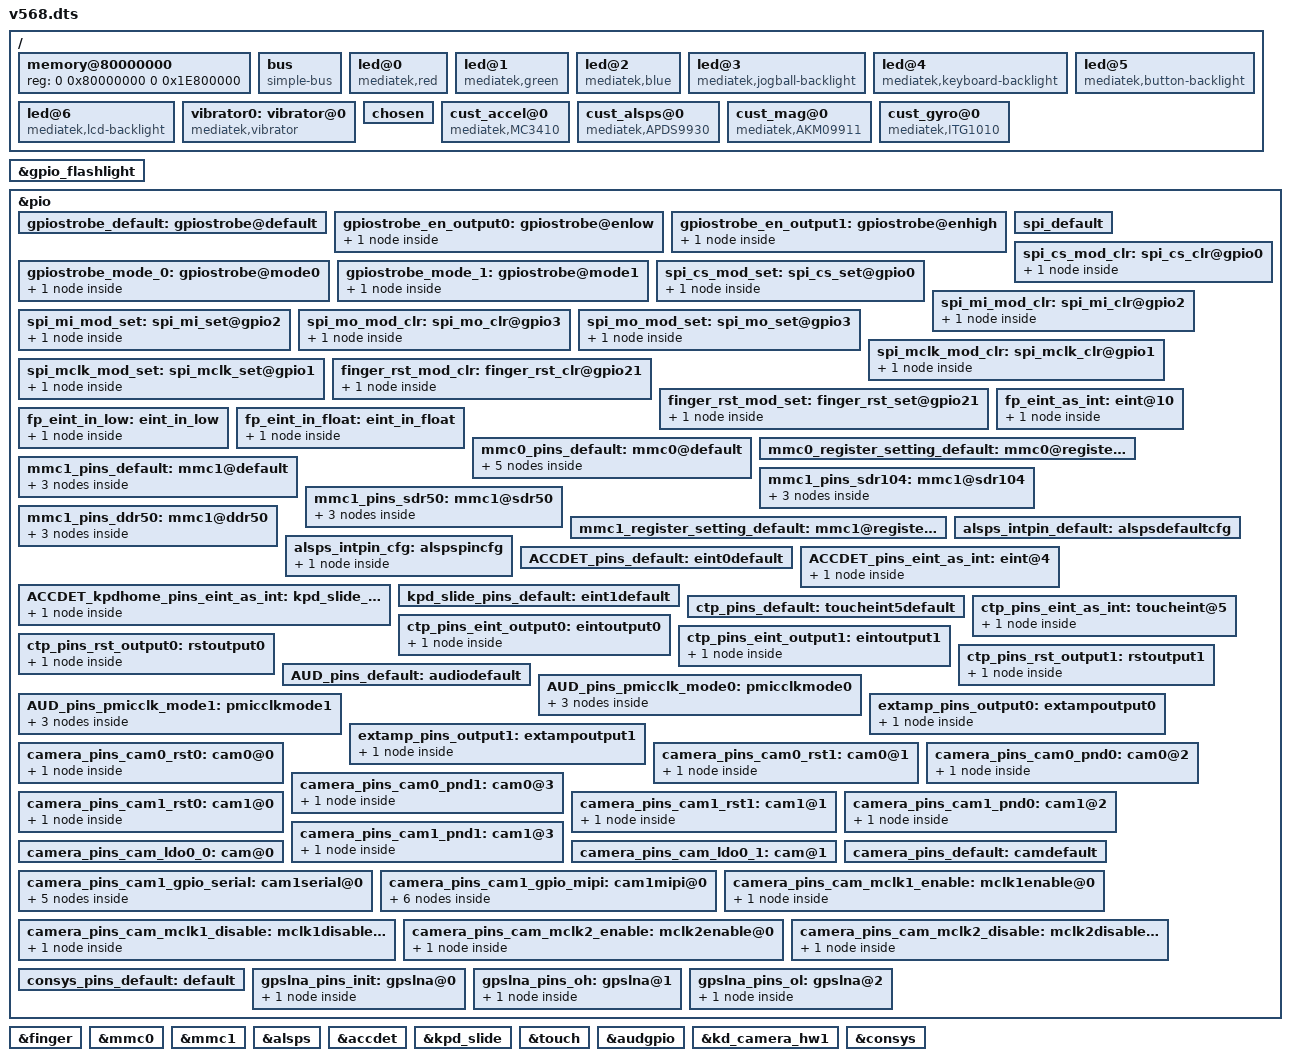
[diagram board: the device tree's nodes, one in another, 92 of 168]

/dts-v1/;

#include "mt6580.dtsi"

/ {
	memory@80000000 {
		device_type = "memory";
		reg = <0 0x80000000 0 0x1E800000>;
	};

	bus {
		compatible = "simple-bus";
		#address-cells = <1>;
		#size-cells = <1>;
		ranges = <0 0 0 0xffffffff>;
	};

	led@0 {
		compatible = "mediatek,red";
		led_mode = <0>;
		data = <1>;
		pwm_config = <0 0 0 0 0>;
	};
	led@1 {
		compatible = "mediatek,green";
		led_mode = <0>;
		data = <1>;
		pwm_config = <0 0 0 0 0>;
	};
	led@2 {
		compatible = "mediatek,blue";
		led_mode = <0>;
		data = <1>;
		pwm_config = <0 0 0 0 0>;
	};
	led@3 {
		compatible = "mediatek,jogball-backlight";
		led_mode = <0>;
		data = <1>;
		pwm_config = <0 0 0 0 0>;
	};
	led@4 {
		compatible = "mediatek,keyboard-backlight";
		led_mode = <0>;
		data = <1>;
		pwm_config = <0 0 0 0 0>;
	};
	led@5 {
		compatible = "mediatek,button-backlight";
		led_mode = <3>;
		data = <4>;
		pwm_config = <0 0 0 0 0>;
	};
	led@6 {
		compatible = "mediatek,lcd-backlight";
		led_mode = <5>;
		data = <1>;
		pwm_config = <0 0 0 0 0>;
	};
	vibrator0:vibrator@0 {
		compatible = "mediatek,vibrator";
		vib_timer = <25>;
		vib_limit = <9>;
		vib_vol= <6>;
	};

	/* chosen */
chosen {
	bootargs = "console=tty0 console=ttyMT0,921600n1 root=/dev/ram initrd=0x84000000,0x400000 loglevel=8";
	/* fpga may has no lk, we need to specify display info here */
	/* fb buffer is reserved using this dts by memory node above */
	atag,videolfb-fb_base = <0x9E800000>;
	atag,videolfb-islcmfound = <1>;
	atag,videolfb-fps= <6000>;
	atag,videolfb-vramSize= <0x01800000>;
	atag,videolfb-lcmname= "nt35590_AUO";
};
	/*  start sensor */
		cust_accel@0 {
		compatible				= "mediatek,MC3410";
		i2c_num					= <2>;
		i2c_addr				= <0x4c 0 0 0>;
		direction				= <4>;
		power_id				= <0xffff>;
		power_vol				= <0>;
		firlen					= <0>;
		is_batch_supported			= <0>;
		};
		cust_alsps@0 {
		compatible				= "mediatek,APDS9930";
		i2c_num					= <2>;
		i2c_addr				= <0x72 0 0 0>;
		polling_mode_ps			= <1>;
		polling_mode_als		= <1>;
		power_id				= <0xffff>;
		power_vol				= <0>;
/* Total has 15 level*/
		als_level	= <0 125 319 525 1091 2480 3058 5115 8589 10769 12857 17807 22091 65535 65535>;
/*  Total has 16 range*/
		als_value	= <0 133 303 504 1002 2003 3006 5003 8002 10000 12000 16000 20000 20000 20000 20000>;
		ps_threshold_high		=  <180>;
		ps_threshold_low		=  <120>;
		is_batch_supported_ps	= <0>;
		is_batch_supported_als	= <0>;
		};
		cust_mag@0 {
		compatible				= "mediatek,AKM09911";
		i2c_num					= <2>;
		i2c_addr				= <0x0D 0 0 0>;
		direction				= <4>;
		power_id				= <0xffff>;
		power_vol				= <0>;
		is_batch_supported			= <0>;
		};
		cust_gyro@0 {
		compatible				= "mediatek,ITG1010";
		i2c_num					= <2>;
		i2c_addr				= <0x68 0 0 0>;
		direction				= <1>;
		power_id				= <0xffff>;
		power_vol				= <0>;
		firlen					= <0>;
		is_batch_supported			= <0>;
		};


  /* end sensor */
};

/* yan add for flashlight with gpio mode */
&gpio_flashlight {
	pinctrl-names = "default", "flash_en_low", "flash_en_high", "flash_mode_0", "flash_mode_1";
	pinctrl-0 = <&gpiostrobe_default>;
	pinctrl-1 = <&gpiostrobe_en_output0>;
	pinctrl-2 = <&gpiostrobe_en_output1>;
	pinctrl-3 = <&gpiostrobe_mode_0>;
	pinctrl-4 = <&gpiostrobe_mode_1>;
	status = "okay";
};
&pio {
	gpiostrobe_default: gpiostrobe@default {
	};
	gpiostrobe_en_output0: gpiostrobe@enlow {
		pins_cmd_dat {
			pins = <PINMUX_GPIO12__FUNC_GPIO12>;
			slew-rate = <1>;
			output-low;
		};
	};
	gpiostrobe_en_output1: gpiostrobe@enhigh {
		pins_cmd_dat {
			pins = <PINMUX_GPIO12__FUNC_GPIO12>;
			slew-rate = <1>;
			output-high;
		};
	};
	gpiostrobe_mode_0: gpiostrobe@mode0 {
		pins_cmd_dat {
			pins = <PINMUX_GPIO15__FUNC_GPIO15>;
		};
	};
	gpiostrobe_mode_1: gpiostrobe@mode1 {
		pins_cmd_dat {
			pins = <PINMUX_GPIO15__FUNC_UCTS1>;
		};
	};
};
/* yan end */

/* add for fingerprint */
&pio {
	spi_default: spi_default {
	};

	spi_cs_mod_clr: spi_cs_clr@gpio0 {
		pins_cmd_dat {
			pins = <PINMUX_GPIO0__FUNC_GPIO0>;
			slew-rate = <1>;
			output-high;
		};
	};
	spi_cs_mod_set: spi_cs_set@gpio0 {
		pins_cmd_dat {
			pins = <PINMUX_GPIO0__FUNC_SPI1_CS>;
			input-enable;
		};
	};	
	spi_mi_mod_clr: spi_mi_clr@gpio2 {
		pins_cmd_dat {
			pins = <PINMUX_GPIO2__FUNC_GPIO2>;
			slew-rate = <1>;
			output-high;
		};
	};
	spi_mi_mod_set: spi_mi_set@gpio2 {
		pins_cmd_dat {
			pins = <PINMUX_GPIO2__FUNC_SPI1_MISO>;
			input-enable;
		};
	};	
	spi_mo_mod_clr: spi_mo_clr@gpio3 {
		pins_cmd_dat {
			pins = <PINMUX_GPIO3__FUNC_GPIO3>;
			slew-rate = <1>;
			output-low;
		};
	};
	spi_mo_mod_set: spi_mo_set@gpio3 {
		pins_cmd_dat {
			pins = <PINMUX_GPIO3__FUNC_SPI1_MOSI>;
			input-enable;
		};
	};	
	spi_mclk_mod_clr: spi_mclk_clr@gpio1 {
		pins_cmd_dat {
			pins = <PINMUX_GPIO1__FUNC_GPIO1>;
			slew-rate = <1>;
			output-low;
		};
	};
	spi_mclk_mod_set: spi_mclk_set@gpio1{
		pins_cmd_dat {
			pins = <PINMUX_GPIO1__FUNC_SPI1_SCK>;
			input-enable;
		};
	};	
	finger_rst_mod_clr: finger_rst_clr@gpio21 {
		pins_cmd_dat {
			pins = <PINMUX_GPIO21__FUNC_GPIO21>;
			slew-rate = <1>;
			output-low;
		};
	};
	finger_rst_mod_set: finger_rst_set@gpio21 {
		pins_cmd_dat {
			pins = <PINMUX_GPIO21__FUNC_GPIO21>;
			slew-rate = <1>;
			output-high;
		};
	};
	fp_eint_as_int: eint@10 {
		pins_cmd_dat {
			pins = <PINMUX_GPIO10__FUNC_EINT10>;
			slew-rate = <0>;
			bias-disable;
		};
	};
	fp_eint_in_low: eint_in_low {
		pins_cmd_dat {
			pins = <PINMUX_GPIO10__FUNC_GPIO10>;
			slew-rate = <1>;
			output-low;
			bias-pull-down = <00>;
		};
	};
	fp_eint_in_float: eint_in_float {
		pins_cmd_dat {
			pins = <PINMUX_GPIO10__FUNC_GPIO10>;
			slew-rate = <1>;
			output-high;
			bias-pull-down = <00>;
		};
	};	
/*fp_pow_mod_clr: finger_pow_clr@gpio15 {
		pins_cmd_dat {
			pins = <PINMUX_GPIO15__FUNC_GPIO15>;
			slew-rate = <1>;
			output-low;
		};
	};
	fp_pow_mod_set: finger_pow_set@gpio15 {
		pins_cmd_dat {
			pins = <PINMUX_GPIO15__FUNC_GPIO15>;
			slew-rate = <1>;
			output-high;
		};
	};	*/
};

&finger {
	pinctrl-names = "spi_default", "spi_cs_clr","spi_cs_set","spi_mi_clr","spi_mi_set",
					"spi_mo_clr","spi_mo_set","spi_mclk_clr","spi_mclk_set",
					"finger_rst_clr","finger_rst_set","eint","eint_clr","eint_set","finger_pow_clr","finger_pow_set";
	pinctrl-0 = <&spi_default>;
	pinctrl-1 = <&spi_cs_mod_clr>;
	pinctrl-2 = <&spi_cs_mod_set>;
	pinctrl-3 = <&spi_mi_mod_clr>;
	pinctrl-4 = <&spi_mi_mod_set>;
	pinctrl-5 = <&spi_mo_mod_clr>;
	pinctrl-6 = <&spi_mo_mod_set>;
	pinctrl-7 = <&spi_mclk_mod_clr>;
	pinctrl-8 = <&spi_mclk_mod_set>;	
	pinctrl-9 = <&finger_rst_mod_clr>;
	pinctrl-10 = <&finger_rst_mod_set>;
	pinctrl-11 = <&fp_eint_as_int>;
	pinctrl-12 = <&fp_eint_in_low>;
	pinctrl-13 = <&fp_eint_in_float>;
/*	pinctrl-14 = <&fp_pow_mod_clr>;
	pinctrl-15 = <&fp_pow_mod_set>;	*/
	status = "okay";
};
/* add end*/

/* mmc start */
&mmc0 {
	clk_src = /bits/ 8 <MSDC0_CLKSRC_208MHZ>;
	bus-width = <8>;
	max-frequency = <208000000>;
	cap-mmc-highspeed;
	msdc-sys-suspend;
	mmc-hs200-1_8v;
	non-removable;
	pinctl = <&mmc0_pins_default>;
	register_setting = <&mmc0_register_setting_default>;
	host_function = /bits/ 8 <MSDC_EMMC>;
	bootable;
	status = "okay";
};

&mmc1 {
	clk_src = /bits/ 8 <MSDC1_CLKSRC_187MHZ>;
	bus-width = <4>;
	max-frequency = <208000000>;
	msdc-sys-suspend;
	cap-sd-highspeed;
	sd-uhs-sdr12;
	sd-uhs-sdr25;
	sd-uhs-sdr50;
	sd-uhs-sdr104;
	pinctl = <&mmc1_pins_default>;
	pinctl_sdr104 = <&mmc1_pins_sdr104>;
	pinctl_sdr50 = <&mmc1_pins_sdr50>;
	pinctl_ddr50 = <&mmc1_pins_ddr50>;
	register_setting = <&mmc1_register_setting_default>;
	host_function = /bits/ 8 <MSDC_SD>;
	cd_level = /bits/ 8 <MSDC_CD_LOW>;
	cd-gpios = <&pio 16 0>;
	status = "okay";
};

&pio {
	mmc0_pins_default: mmc0@default {
		pins_cmd {
			drive-strength = /bits/ 8 <2>;
		};
		pins_dat {
			drive-strength = /bits/ 8 <2>;
		};
		pins_clk {
			drive-strength = /bits/ 8 <2>;
		};
		pins_rst {
			drive-strength = /bits/ 8 <2>;
		};
		pins_ds {
			drive-strength = /bits/ 8 <2>;
		};
	};

	mmc0_register_setting_default: mmc0@register_default {
		dat0rddly      = /bits/ 8 <0>;
		dat1rddly      = /bits/ 8 <0>;
		dat2rddly      = /bits/ 8 <0>;
		dat3rddly      = /bits/ 8 <0>;
		dat4rddly      = /bits/ 8 <0>;
		dat5rddly      = /bits/ 8 <0>;
		dat6rddly      = /bits/ 8 <0>;
		dat7rddly      = /bits/ 8 <0>;
		datwrddly      = /bits/ 8 <0>;
		cmdrrddly      = /bits/ 8 <0>;
		cmdrddly       = /bits/ 8 <0>;
		cmd_edge = /bits/ 8 <MSDC_SMPL_FALLING>;
		rdata_edge = /bits/ 8 <MSDC_SMPL_FALLING>;
		wdata_edge = /bits/ 8 <MSDC_SMPL_FALLING>;

		ett-hs200-cells = <12>;
		ett-hs200-default = <OFFSET_MSDC_PATCH_BIT0	MSDC_PB0_INT_DAT_LATCH_CK_SEL 0x0
			OFFSET_MSDC_PATCH_BIT0  MSDC_PB0_CKGEN_MSDC_DLY_SEL   0x0
			OFFSET_MSDC_PATCH_BIT1  MSDC_PB1_CMD_RSP_TA_CNTR      0x1
			OFFSET_MSDC_IOCON       MSDC_IOCON_RSPL               0x1
			OFFSET_MSDC_PAD_TUNE0   MSDC_PAD_TUNE0_CMDRDLY        0x0
			OFFSET_MSDC_PAD_TUNE0   MSDC_PAD_TUNE0_CMDRRDLY       0x0
			OFFSET_MSDC_PATCH_BIT1  MSDC_PB1_WRDAT_CRCS_TA_CNTR   0x1
			OFFSET_MSDC_PAD_TUNE0   MSDC_PAD_TUNE0_DATWRDLY       0x0
			OFFSET_MSDC_IOCON       MSDC_IOCON_W_D_SMPL           0x1
			OFFSET_MSDC_DAT_RDDLY0  MSDC_DAT_RDDLY0_D0            0x0
			OFFSET_MSDC_PAD_TUNE0   MSDC_PAD_TUNE0_DATRRDLY       0x0
			OFFSET_MSDC_PATCH_BIT0  MSDC_PB0_RD_DAT_SEL           0x1>;
	};

	mmc1_pins_default: mmc1@default {
		pins_cmd {
			drive-strength = /bits/ 8 <3>;
		};
		pins_dat {
			drive-strength = /bits/ 8 <3>;
		};
		pins_clk {
			drive-strength = /bits/ 8 <3>;
		};
	};

	mmc1_pins_sdr104: mmc1@sdr104 {
		pins_cmd {
			drive-strength = /bits/ 8 <2>;
		};
		pins_dat {
			drive-strength = /bits/ 8 <2>;
		};
		pins_clk {
			drive-strength = /bits/ 8 <3>;
		};
	};

	mmc1_pins_sdr50: mmc1@sdr50 {
		pins_cmd {
			drive-strength = /bits/ 8 <2>;
		};
		pins_dat {
			drive-strength = /bits/ 8 <2>;
		};
		pins_clk {
			drive-strength = /bits/ 8 <3>;
		};
	};

	mmc1_pins_ddr50: mmc1@ddr50 {
		pins_cmd {
			drive-strength = /bits/ 8 <2>;
		};
		pins_dat {
			drive-strength = /bits/ 8 <2>;
		};
		pins_clk {
			drive-strength = /bits/ 8 <3>;
		};
	};

	mmc1_register_setting_default: mmc1@register_default {
		dat0rddly      = /bits/ 8 <0>;
		dat1rddly      = /bits/ 8 <0>;
		dat2rddly      = /bits/ 8 <0>;
		dat3rddly      = /bits/ 8 <0>;
		datwrddly      = /bits/ 8 <0>;
		cmdrrddly      = /bits/ 8 <0>;
		cmdrddly       = /bits/ 8 <0>;
		cmd_edge = /bits/ 8 <MSDC_SMPL_FALLING>;
		rdata_edge = /bits/ 8 <MSDC_SMPL_FALLING>;
		wdata_edge = /bits/ 8 <MSDC_SMPL_FALLING>;
	};
};
/* mmc end */


&alsps {
	pinctrl-names = "pin_default", "pin_cfg";
	pinctrl-0 = <&alsps_intpin_default>;
	pinctrl-1 = <&alsps_intpin_cfg>;
	status = "okay";
};

/*
&gyro {
	pinctrl-names = "pin_default", "pin_cfg";
	pinctrl-0 = <&gyro_intpin_default>;
	pinctrl-1 = <&gyro_intpin_cfg>;
	status = "okay";
};
*/
&pio {

	alsps_intpin_default: alspsdefaultcfg {
	};
	alsps_intpin_cfg: alspspincfg {
	    pins_cmd_dat {
			pins = <PINMUX_GPIO6__FUNC_EINT6>;
		};
	};	
/*	
	gyro_intpin_cfg: gyropincfg {
	    pins_cmd_dat {
			pins = <PINMUX_GPIO16__FUNC_GPIO16>;
			slew-rate = <0>;
			bias-pull-down = <00>;
		};
	};
	gyro_intpin_default: gyrodefaultcfg {
	};
	*/
};

&accdet {
	accdet-mic-vol = <7>;
	headset-mode-setting = <0x500 0x200 1 0x1F0 0x800 0x800 0x20>;
	accdet-plugout-debounce = <20>;
	/*1:ACC mode, 2:low cost without in bias, 6:low cost with in bias*/
	accdet-mic-mode = <1>;
	/*0--MD_MAX--UP_MAX--DW_MAX*/
	headset-three-key-threshold = <0 90 240 500>;
	/*0--MD_MAX--VOICE_MAX--UP_MAX--DW_MAX*/
	headset-four-key-threshold = <0 59 123 195 450>;
	/* ACCDET GPIO standardization ACC mode use */
	pinctrl-names = "default", "state_eint_as_int", "kpdhome_state_eint_as_int"/*, "sd_msdc_eint_as_int", "sim_hot_plug_1", "sim_hot_plug_2"*/;
	pinctrl-0 = <&ACCDET_pins_default>;
	pinctrl-1 = <&ACCDET_pins_eint_as_int>;
	pinctrl-2 = <&ACCDET_kpdhome_pins_eint_as_int>;
/*		pinctrl-3 = <&msdc_eint_as_int>;
    pinctrl-4 = <&ACCDET_sim_hot_plug_1>;
	pinctrl-5 = <&ACCDET_sim_hot_plug_2>; */
	status = "okay";
};
&pio {
	ACCDET_pins_default: eint0default {
	};
	ACCDET_pins_eint_as_int: eint@4 {
		pins_cmd_dat {
			pins = <PINMUX_GPIO4__FUNC_EINT4>;
			slew-rate = <0>;
			bias-disable;
		};
	};
	ACCDET_kpdhome_pins_eint_as_int: eint@1 {
		pins_cmd_dat {
			pins = <PINMUX_GPIO65__FUNC_EINT1>;
			slew-rate = <0>;
			bias-disable;
		};
	};	
/*	msdc_eint_as_int: eint@0 {
		pins_cmd_dat {
			pins = <PINMUX_GPIO16__FUNC_EINT0>;
			slew-rate = <0>;
			bias-disable;
		};
	};
	ACCDET_sim_hot_plug_1: mt_enit@1 {
		pins_cmd_dat {
			pins = <PINMUX_GPIO77__FUNC_MD_EINT1>;
		};
	};		
	ACCDET_sim_hot_plug_2: mt_enit@2 {
		pins_cmd_dat {
			pins = <PINMUX_GPIO78__FUNC_MD_EINT2>;
		};
	}; */
};
/*ACCDET END*/


/*kpdslide begin*/
&kpd_slide{
	pinctrl-0 = <&kpd_slide_pins_default>;
	pinctrl-1 = <&kpd_slide_pins_eint_as_int>;
	status = "okay";
};
&pio {
	kpd_slide_pins_default: eint1default {
	};
	kpd_slide_pins_eint_as_int: eint@1 {
		pins_cmd_dat {
			pins = <PINMUX_GPIO65__FUNC_EINT1>;
			slew-rate = <0>;
			bias-disable;
		};
	};
};
/*kpdslide END*/

/* TOUCH GPIO standardization */
&touch {
	tpd-resolution = <720 1280>;
	use-tpd-button = <0>;
	tpd-key-num = <3>;
	tpd-key-local= <139 172 158 0>;
	tpd-key-dim-local = <90 883 100 40 230 883 100 40 370 883 100 40 0 0 0 0>;
	tpd-max-touch-num = <5>;
	tpd-filter-enable = <1>;
	tpd-filter-pixel-density = <124>;
	tpd-filter-custom-prameters = <0 0 0 0 0 0 0 0 0 0 0 0>;
	tpd-filter-custom-speed = <0 0 0>;
	pinctrl-names = "default", "state_eint_as_int", "state_eint_output0", "state_eint_output1",
		"state_rst_output0", "state_rst_output1";
	pinctrl-0 = <&ctp_pins_default>;
	pinctrl-1 = <&ctp_pins_eint_as_int>;
	pinctrl-2 = <&ctp_pins_eint_output0>;
	pinctrl-3 = <&ctp_pins_eint_output1>;
	pinctrl-4 = <&ctp_pins_rst_output0>;
	pinctrl-5 = <&ctp_pins_rst_output1>;
	status = "okay";
};
&pio {
	ctp_pins_default: toucheint5default {
	};
	ctp_pins_eint_as_int: toucheint@5 {
		pins_cmd_dat {
			pins = <PINMUX_GPIO5__FUNC_EINT5>;
			slew-rate = <0>;
			bias-disable;
		};
	};
	ctp_pins_eint_output0: eintoutput0 {
		pins_cmd_dat {
			pins = <PINMUX_GPIO5__FUNC_GPIO5>;
			slew-rate = <1>;
			output-low;
		};
	};
	ctp_pins_eint_output1: eintoutput1 {
		pins_cmd_dat {
			pins = <PINMUX_GPIO5__FUNC_GPIO5>;
			slew-rate = <1>;
			output-high;
		};
	};
	ctp_pins_rst_output0: rstoutput0 {
		pins_cmd_dat {
			pins = <PINMUX_GPIO11__FUNC_GPIO11>;
			slew-rate = <1>;
			output-low;
		};
	};
	ctp_pins_rst_output1: rstoutput1 {
		pins_cmd_dat {
			pins = <PINMUX_GPIO11__FUNC_GPIO11>;
			slew-rate = <1>;
			output-high;
		};
	};
};
/* TOUCH end */

/* AUDIO GPIO standardization */
&audgpio {
	pinctrl-names = "default", "audpmicclk-mode0", "audpmicclk-mode1", "extamp-pulllow", "extamp-pullhigh";
	pinctrl-0 = <&AUD_pins_default>;
	pinctrl-1 = <&AUD_pins_pmicclk_mode0>;
	pinctrl-2 = <&AUD_pins_pmicclk_mode1>;
	pinctrl-3 = <&extamp_pins_output0>;
	pinctrl-4 = <&extamp_pins_output1>;
	status = "okay";
};
&pio {
	AUD_pins_default: audiodefault {
	};
	AUD_pins_pmicclk_mode0: pmicclkmode0 {
		pins_cmd0_dat {
			pins = <PINMUX_GPIO26__FUNC_GPIO26>;
		};
		pins_cmd1_dat {
			pins = <PINMUX_GPIO28__FUNC_GPIO28>;
		};
		pins_cmd2_dat {
			pins = <PINMUX_GPIO27__FUNC_GPIO27>;
		};
	};
	AUD_pins_pmicclk_mode1: pmicclkmode1 {
		pins_cmd0_dat {
			pins = <PINMUX_GPIO26__FUNC_AUD_CLK_MOSI>;
		};
		pins_cmd1_dat {
			pins = <PINMUX_GPIO28__FUNC_AUD_DAT_MISO>;
		};
		pins_cmd2_dat {
			pins = <PINMUX_GPIO27__FUNC_AUD_DAT_MOSI>;
		};
	};
	extamp_pins_output0: extampoutput0 {
		pins_cmd_dat {
			pins = <PINMUX_GPIO9__FUNC_GPIO9>;
			slew-rate = <1>;
			output-low;
		};
	};
	extamp_pins_output1: extampoutput1 {
		pins_cmd_dat {
			pins = <PINMUX_GPIO9__FUNC_GPIO9>;
			slew-rate = <1>;
			output-high;
		};
	};
};
/* AUDIO end */
/* CAMERA GPIO standardization */
&pio {
	camera_pins_cam0_rst0: cam0@0 {
	    pins_cmd_dat {
			pins = <PINMUX_GPIO73__FUNC_GPIO73>;/*GPIO_CAMERA_CMRST_PIN*/
			slew-rate = <1>; /*direction 0:in, 1:out*/
			output-low;/*direction out used only. output_low or high*/
		};
	};
	camera_pins_cam0_rst1: cam0@1 {
	    pins_cmd_dat {
			pins = <PINMUX_GPIO73__FUNC_GPIO73>;/*GPIO_CAMERA_CMRST_PIN*/
			slew-rate = <1>;
			output-high;
		};
	};
	camera_pins_cam0_pnd0: cam0@2 {
	    pins_cmd_dat {
			pins = <PINMUX_GPIO71__FUNC_GPIO71>;/*GPIO_CAMERA_CMPDN_PIN*/
			slew-rate = <1>;
			output-low;
		};
	};
	camera_pins_cam0_pnd1: cam0@3 {
	    pins_cmd_dat {
			pins = <PINMUX_GPIO71__FUNC_GPIO71>;/*GPIO_CAMERA_CMPDN_PIN*/
			slew-rate = <1>;
			output-high;
		};
	};
	camera_pins_cam1_rst0: cam1@0 {
	    pins_cmd_dat {
			pins = <PINMUX_GPIO76__FUNC_GPIO76>;/*GPIO_CAMERA_CMRST1_PIN*/
			slew-rate = <1>; /*direction 0:in, 1:out*/
			output-low;/*direction out used only. output_low or high*/
		};
	};
	camera_pins_cam1_rst1: cam1@1 {
	    pins_cmd_dat {
			pins = <PINMUX_GPIO76__FUNC_GPIO76>;/*GPIO_CAMERA_CMRST1_PIN*/
			slew-rate = <1>;
			output-high;
		};
	};
	camera_pins_cam1_pnd0: cam1@2 {
	    pins_cmd_dat {
			pins = <PINMUX_GPIO74__FUNC_GPIO74>;/*GPIO_CAMERA_CMPDN1_PIN*/
			slew-rate = <1>;
			output-high;
		};
	};
	camera_pins_cam1_pnd1: cam1@3 {
	    pins_cmd_dat {
			pins = <PINMUX_GPIO74__FUNC_GPIO74>;/*GPIO_CAMERA_CMPDN1_PIN*/
			slew-rate = <1>;
			output-low;
		};
	};
	camera_pins_cam_ldo0_0: cam@0 {
	};
	camera_pins_cam_ldo0_1: cam@1 {
	};
	camera_pins_default: camdefault {
	};
	camera_pins_cam1_gpio_serial: cam1serial@0{
	    pins_cmd_dat {
			pins = <PINMUX_GPIO35__FUNC_CMCSK>;
		};
	    pins_cmd_dat1 {
			pins = <PINMUX_GPIO36__FUNC_CMCSD0>;
		};
	    pins_cmd_dat2 {
			pins = <PINMUX_GPIO37__FUNC_CMCSD1>;
		};
	    pins_cmd_dat3 {
			pins = <PINMUX_GPIO38__FUNC_CMCSD2>;
		};
	    pins_cmd_dat4 {
			pins = <PINMUX_GPIO39__FUNC_CMCSD3>;
		};
	};
	camera_pins_cam1_gpio_mipi: cam1mipi@0{
	    pins_cmd_dat {
			pins = <PINMUX_GPIO35__FUNC_PAD_RDP0_A>;
		};
	    pins_cmd_dat1 {
			pins = <PINMUX_GPIO36__FUNC_PAD_RDN0_A>;
		};
	    pins_cmd_dat2 {
			pins = <PINMUX_GPIO37__FUNC_PAD_RDP1_A>;
		};
	    pins_cmd_dat3 {
			pins = <PINMUX_GPIO38__FUNC_PAD_RDN1_A>;
		};
	    pins_cmd_dat4 {
			pins = <PINMUX_GPIO39__FUNC_PAD_RCP_A>;
		};
	    pins_cmd_dat5 {
			pins = <PINMUX_GPIO40__FUNC_PAD_RCN_A>;
		};
	};
	camera_pins_cam_mclk1_enable: mclk1enable@0{
		pins_cmd_dat {
			pins = <PINMUX_GPIO72__FUNC_CAM_CLK0>;
		};
	};
	camera_pins_cam_mclk1_disable: mclk1disable@0{
	   pins_cmd_dat {
			pins = <PINMUX_GPIO72__FUNC_GPIO72>;
		};
	};
	camera_pins_cam_mclk2_enable: mclk2enable@0{
		pins_cmd_dat {
			pins = <PINMUX_GPIO75__FUNC_CAM_CLK1>;
		};
	};
	camera_pins_cam_mclk2_disable: mclk2disable@0{
		pins_cmd_dat {
			pins = <PINMUX_GPIO75__FUNC_GPIO75>;
		};
	};


};
&kd_camera_hw1 {
	pinctrl-names = "default", "cam0_rst0", "cam0_rst1", "cam0_pnd0", "cam0_pnd1",
				   "cam1_rst0", "cam1_rst1", "cam1_pnd0", "cam1_pnd1",
				   "cam_ldo0_0", "cam_ldo0_1", "cam1_gpio_serial", "cam1_gpio_mipi",
				   "cam_mclk1_enable","cam_mclk1_disable",
				   "cam_mclk2_enable","cam_mclk2_disable";
	pinctrl-0 = <&camera_pins_default>;
	pinctrl-1 = <&camera_pins_cam0_rst0>;
	pinctrl-2 = <&camera_pins_cam0_rst1>;
	pinctrl-3 = <&camera_pins_cam0_pnd0>;
	pinctrl-4 = <&camera_pins_cam0_pnd1>;
	pinctrl-5 = <&camera_pins_cam1_rst0>;
	pinctrl-6 = <&camera_pins_cam1_rst1>;
	pinctrl-7 = <&camera_pins_cam1_pnd0>;
	pinctrl-8 = <&camera_pins_cam1_pnd1>;
	pinctrl-9 = <&camera_pins_cam_ldo0_0>;
	pinctrl-10 = <&camera_pins_cam_ldo0_1>;
	pinctrl-11 = <&camera_pins_cam1_gpio_serial>;
	pinctrl-12 = <&camera_pins_cam1_gpio_mipi>;
	pinctrl-13 = <&camera_pins_cam_mclk1_enable>;
	pinctrl-14 = <&camera_pins_cam_mclk1_disable>;
	pinctrl-15 = <&camera_pins_cam_mclk2_enable>;
	pinctrl-16 = <&camera_pins_cam_mclk2_disable>;

	status = "okay";
};
/* CAMERA GPIO end */

/* CONSYS GPIO standardization */
&pio {
	consys_pins_default: default {

	};

	gpslna_pins_init: gpslna@0 {

		pins_cmd_dat {
			pins = <PINMUX_GPIO14__FUNC_GPIO14>;
			slew-rate = <0>;
			bias-disable;
			output-low;
		};
	};

	gpslna_pins_oh: gpslna@1 {

		pins_cmd_dat {
			pins = <PINMUX_GPIO14__FUNC_GPIO14>;
			slew-rate = <1>;
			output-high;
		};
	};

	gpslna_pins_ol: gpslna@2 {

		pins_cmd_dat {
			pins = <PINMUX_GPIO14__FUNC_GPIO14>;
			slew-rate = <1>;
			output-low;
		};
	};

};

&consys {
	pinctrl-names = "default", "gps_lna_state_init", "gps_lna_state_oh", "gps_lna_state_ol";
	pinctrl-0 = <&consys_pins_default>;
	pinctrl-1 = <&gpslna_pins_init>;
	pinctrl-2 = <&gpslna_pins_oh>;
	pinctrl-3 = <&gpslna_pins_ol>;
	status = "okay";

};
/* CONSYS end */
